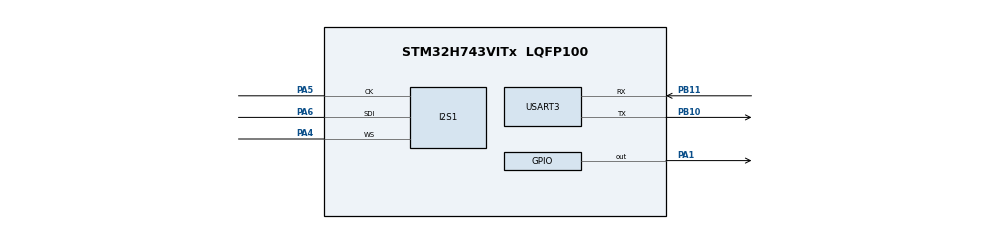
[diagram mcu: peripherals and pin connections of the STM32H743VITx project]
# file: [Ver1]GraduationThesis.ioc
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CORTEX_M7.CPU_DCache=Enabled
CORTEX_M7.CPU_ICache=Enabled
CORTEX_M7.default_mode_Activation=1
Dma.Request0=SPI1_RX
Dma.SPI1_RX.0.Direction=DMA_PERIPH_TO_MEMORY
Dma.SPI1_RX.0.EventEnable=DISABLE
Dma.SPI1_RX.0.FIFOMode=DMA_FIFOMODE_DISABLE
Dma.SPI1_RX.0.Instance=DMA1_Stream0
Dma.SPI1_RX.0.MemDataAlignment=DMA_MDATAALIGN_HALFWORD
Dma.SPI1_RX.0.MemInc=DMA_MINC_ENABLE
Dma.SPI1_RX.0.Mode=DMA_CIRCULAR
Dma.SPI1_RX.0.PeriphDataAlignment=DMA_PDATAALIGN_HALFWORD
Dma.SPI1_RX.0.PeriphInc=DMA_PINC_DISABLE
Dma.SPI1_RX.0.Polarity=HAL_DMAMUX_REQ_GEN_RISING
Dma.SPI1_RX.0.Priority=DMA_PRIORITY_LOW
Dma.SPI1_RX.0.RequestNumber=1
Dma.SPI1_RX.0.SignalID=NONE
Dma.SPI1_RX.0.SyncEnable=DISABLE
Dma.SPI1_RX.0.SyncPolarity=HAL_DMAMUX_SYNC_NO_EVENT
Dma.SPI1_RX.0.SyncRequestNumber=1
Dma.SPI1_RX.0.SyncSignalID=NONE
I2S1.AudioFreq=I2S_AUDIOFREQ_48K
I2S1.ErrorAudioFreq=0.15 %
I2S1.Instance=SPI$Index
I2S1.RealAudioFreq=48.076 KHz
Mcu.Family=STM32H7
Mcu.Name=STM32H743VITx
Mcu.Package=LQFP100
NVIC.DMA1_Stream0_IRQn=true\:0\:0\:false\:false\:true\:false\:true\:true
NVIC.PriorityGroup=NVIC_PRIORITYGROUP_4
NVIC.USART3_IRQn=true\:0\:0\:false\:false\:true\:true\:true\:true
PA1.Signal=GPIO_Output
PA4.Mode=Half_Duplex_Master_Rx
PA4.Signal=I2S1_WS
PA5.Mode=Half_Duplex_Master_Rx
PA5.Signal=I2S1_CK
PA6.Mode=Half_Duplex_Master_Rx
PA6.Signal=I2S1_SDI
PB10.Mode=Asynchronous
PB10.Signal=USART3_TX
PB11.Mode=Asynchronous
PB11.Signal=USART3_RX
PH0-OSC_IN\ (PH0).Mode=HSE-External-Oscillator
PH0-OSC_IN\ (PH0).Signal=RCC_OSC_IN
PH1-OSC_OUT\ (PH1).Mode=HSE-External-Oscillator
PH1-OSC_OUT\ (PH1).Signal=RCC_OSC_OUT
ProjectManager.HeapSize=0x800
ProjectManager.StackSize=0x800
ProjectManager.TargetToolchain=STM32CubeIDE
RCC.ADCFreq_Value=12307692.307692308
RCC.APB1CLKDivider=RCC_HCLK_DIV4
RCC.APB1Freq_Value=120000000
RCC.APB2CLKDivider=RCC_HCLK_DIV2
RCC.APB2Freq_Value=120000000
RCC.APB3Freq_Value=120000000
RCC.APB4Freq_Value=120000000
RCC.CortexFreq_Value=480000000
RCC.D1PPRE=RCC_APB3_DIV2
RCC.D2PPRE1=RCC_APB1_DIV2
RCC.D2PPRE2=RCC_APB2_DIV2
RCC.D3PPRE=RCC_APB4_DIV2
RCC.DIVM1=5
RCC.DIVM2=5
RCC.DIVM3=4
RCC.DIVN1=192
RCC.DIVN2=192
RCC.DIVN3=480
RCC.DIVP2=78
RCC.DIVQ1=20
RCC.DIVQ2=20
RCC.DIVQ3=8
RCC.DIVR2=20
RCC.HCLKFreq_Value=240000000
RCC.HPRE=RCC_HCLK_DIV2
RCC.HSE_VALUE=25000000
RCC.PLLM=25
RCC.PLLMUL=RCC_PLL_MUL9
RCC.PLLN=432
RCC.PLLQ=9
RCC.PLLSourceVirtual=RCC_PLLSOURCE_HSE
RCC.PRESCALERUSB=RCC_USBCLKSOURCE_PLL_DIV1_5
RCC.SPI123CLockSelection=RCC_SPI123CLKSOURCE_PLL2
RCC.SYSCLKFreq_VALUE=480000000
RCC.SYSCLKSource=RCC_SYSCLKSOURCE_PLLCLK
RCC.SYSCLKSourceVirtual=RCC_SYSCLKSOURCE_PLLCLK
RCC.USBFreq_Value=48000000
STMicroelectronics.X-CUBE-AI.10.2.0.ActivationBufferSizeList=127252
STMicroelectronics.X-CUBE-AI.10.2.0.ActivationBuffers=pool0
STMicroelectronics.X-CUBE-AI.10.2.0.ActivationNames=pool0
STMicroelectronics.X-CUBE-AI.10.2.0.ActivationSizes=AI_NETWORK_4_DATA_ACTIVATION_1_SIZE
STMicroelectronics.X-CUBE-AI.10.2.0.ApplicationCcDeviceJjApplication=ApplicationTemplate
STMicroelectronics.X-CUBE-AI.10.2.0.HeapSize=0x800
STMicroelectronics.X-CUBE-AI.10.2.0.InternalRamActivationBufferMaxSize=AI_NETWORK_4_DATA_ACTIVATIONS_SIZE
STMicroelectronics.X-CUBE-AI.10.2.0.LatestDirectoryUsed-b0ac161f105402a51aeaffc1b3403c077ace8f8e6b938b9991d97e17c2f4d924=D\:\\ML
STMicroelectronics.X-CUBE-AI.10.2.0.MaximumNumberOfInputLayer=1
STMicroelectronics.X-CUBE-AI.10.2.0.MaximumNumberOfOutputLayer=1
STMicroelectronics.X-CUBE-AI.10.2.0.MaximumSizeOfInputLayer=1
STMicroelectronics.X-CUBE-AI.10.2.0.MaximumSizeOfOutputLayer=1
STMicroelectronics.X-CUBE-AI.10.2.0.ModelActualCompression-b0ac161f105402a51aeaffc1b3403c077ace8f8e6b938b9991d97e17c2f4d924=0.0
STMicroelectronics.X-CUBE-AI.10.2.0.ModelCompression-b0ac161f105402a51aeaffc1b3403c077ace8f8e6b938b9991d97e17c2f4d924=None
STMicroelectronics.X-CUBE-AI.10.2.0.ModelFlashOccupation-b0ac161f105402a51aeaffc1b3403c077ace8f8e6b938b9991d97e17c2f4d924=55082
STMicroelectronics.X-CUBE-AI.10.2.0.ModelHashList=b0ac161f105402a51aeaffc1b3403c077ace8f8e6b938b9991d97e17c2f4d924
STMicroelectronics.X-CUBE-AI.10.2.0.ModelKind-b0ac161f105402a51aeaffc1b3403c077ace8f8e6b938b9991d97e17c2f4d924=TFLITE
STMicroelectronics.X-CUBE-AI.10.2.0.ModelMacc-b0ac161f105402a51aeaffc1b3403c077ace8f8e6b938b9991d97e17c2f4d924=1861855
STMicroelectronics.X-CUBE-AI.10.2.0.ModelName-b0ac161f105402a51aeaffc1b3403c077ace8f8e6b938b9991d97e17c2f4d924=network_4
STMicroelectronics.X-CUBE-AI.10.2.0.ModelNameList=network_4
STMicroelectronics.X-CUBE-AI.10.2.0.ModelRamOccupation-b0ac161f105402a51aeaffc1b3403c077ace8f8e6b938b9991d97e17c2f4d924=127252
STMicroelectronics.X-CUBE-AI.10.2.0.ModelStructureFile-b0ac161f105402a51aeaffc1b3403c077ace8f8e6b938b9991d97e17c2f4d924=D\:\\ML\\light_cnn_0406_003729_final_float32.tflite
STMicroelectronics.X-CUBE-AI.10.2.0.ModelType-b0ac161f105402a51aeaffc1b3403c077ace8f8e6b938b9991d97e17c2f4d924=STM32Cube.AI MCU runtime
STMicroelectronics.X-CUBE-AI.10.2.0.ReadyForCodeGeneration=true
STMicroelectronics.X-CUBE-AI.10.2.0.StackSize=0x800
STMicroelectronics.X-CUBE-AI.10.2.0.WorkingBufferStartAddrList=0xFFFFFFFF
STMicroelectronics.X-CUBE-AI.10.2.0.XAaCUBEAaAICcArtificialOoIntelligenceJjCore=true
STMicroelectronics.X-CUBE-AI.10.2.0.copyWeightToRam=false
STMicroelectronics.X-CUBE-AI.10.2.0.copyWeightToRam-b0ac161f105402a51aeaffc1b3403c077ace8f8e6b938b9991d97e17c2f4d924=false
STMicroelectronics.X-CUBE-AI.10.2.0.customLayerConfigEnabled=false
STMicroelectronics.X-CUBE-AI.10.2.0.customLayerConfigEnabled-b0ac161f105402a51aeaffc1b3403c077ace8f8e6b938b9991d97e17c2f4d924=false
STMicroelectronics.X-CUBE-AI.10.2.0.noOnnxIoTranspose=false
STMicroelectronics.X-CUBE-AI.10.2.0.noOnnxIoTranspose-b0ac161f105402a51aeaffc1b3403c077ace8f8e6b938b9991d97e17c2f4d924=false
STMicroelectronics.X-CUBE-AI.10.2.0.useInputAllocation=true
STMicroelectronics.X-CUBE-AI.10.2.0.useInputAllocation-b0ac161f105402a51aeaffc1b3403c077ace8f8e6b938b9991d97e17c2f4d924=true
STMicroelectronics.X-CUBE-AI.10.2.0.useOutputAllocation=true
STMicroelectronics.X-CUBE-AI.10.2.0.useOutputAllocation-b0ac161f105402a51aeaffc1b3403c077ace8f8e6b938b9991d97e17c2f4d924=true
USART3.VirtualMode-Asynchronous=VM_ASYNC
VP_MEMORYMAP_VS_MEMORYMAP.Mode=CurAppReg
VP_STMicroelectronics.X-CUBE-AI_VS_ArtificialOoIntelligenceJjXAaCUBEAaAI_10.2.0.Mode=ArtificialOoIntelligenceJjXAaCUBEAaAI
VP_STMicroelectronics.X-CUBE-AI_VS_DeviceJjApplication_10.2.0.Mode=DeviceJjApplication
board=custom

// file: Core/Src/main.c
/* USER CODE BEGIN Header */
/**
 ******************************************************************************
 * @file           : main.c
 * @brief          : Main program body
 ******************************************************************************
 */
/* USER CODE END Header */
#include "main.h"
#include "app_x-cube-ai.h"
#include <string.h>
/* USER CODE BEGIN Includes */
#include "audio_capture.h" // định nghĩa FRAME_LEN, HOP_SAMPLES, RING_BUFFER_SIZE
#include "mfcc_extract.h"
#include "debug_uart.h"
/* USER CODE END Includes */
#define INFER_STEP_FRAMES 67U // ~1 giây vì hop = 15 ms

I2S_HandleTypeDef hi2s1;
DMA_HandleTypeDef hdma_spi1_rx;

UART_HandleTypeDef huart3;
static int16_t mfcc_audio_frame[FRAME_LEN];
static uint8_t mfcc_frame_initialized = 0;
static uint32_t new_frames_since_infer = 0;
static uint8_t first_inference_done = 0;
static uint8_t mfcc_window_ready = 0;

void SystemClock_Config(void);
static void MPU_Config(void);
static void MX_GPIO_Init(void);
static void MX_DMA_Init(void);
static void MX_I2S1_Init(void);
static void MX_USART3_UART_Init(void);
void MFCC_LogWindowTiming(void);

/* USER CODE BEGIN 0 */
extern int16_t ring_buffer[];
extern volatile uint32_t rb_write;
extern volatile uint32_t rb_read;
extern float32_t mfcc_final_features[MFCC_FEATURES][MFCC_TIME_FRAMES];
extern uint32_t mfcc_collected;
/* USER CODE END 0 */

int main(void)
{

  /* MPU Configuration--------------------------------------------------------*/
  MPU_Config();

  /* Enable the CPU Cache */

  /* Enable I-Cache---------------------------------------------------------*/
  SCB_EnableICache();

  /* Enable D-Cache---------------------------------------------------------*/
  SCB_EnableDCache();

  /* MCU Configuration--------------------------------------------------------*/

  /* Reset of all peripherals, Initializes the Flash interface and the Systick. */
  HAL_Init();

  /* Configure the system clock */
  SystemClock_Config();

  /* Initialize all configured peripherals */
  MX_GPIO_Init();
  MX_DMA_Init();
  MX_I2S1_Init();
  MX_USART3_UART_Init();
  MX_X_CUBE_AI_Init();

  DebugUART_InitTime();
  DebugUART_Log("Hello STM32H743\r\n");
  /* USER CODE BEGIN 2 */
  Preprocessing_Init();
  StartAudioCapture();
  /* USER CODE END 2 */

  /* Infinite loop */
  /* USER CODE BEGIN WHILE */
  while (1)
  {
    Audio_DebugLog_Process();

    if (!mfcc_frame_initialized)
    {
      if (RingBuffer_Available() >= FRAME_LEN)
      {
        RingBuffer_Read(mfcc_audio_frame, FRAME_LEN);
        mfcc_frame_initialized = 1;
      }
    }

    while (mfcc_frame_initialized &&
           RingBuffer_Available() >= HOP_SAMPLES)
    {
      int16_t hop_buf[HOP_SAMPLES];
      float mfcc_frame[MFCC_FEATURES];

      RingBuffer_Read(hop_buf, HOP_SAMPLES);

      memmove(&mfcc_audio_frame[0],
              &mfcc_audio_frame[HOP_SAMPLES],
              (FRAME_LEN - HOP_SAMPLES) * sizeof(int16_t));

      memcpy(&mfcc_audio_frame[FRAME_LEN - HOP_SAMPLES],
             hop_buf,
             HOP_SAMPLES * sizeof(int16_t));

      compute_mfcc_one_frame_timed(mfcc_audio_frame, mfcc_frame);
      mfcc_append_frame(mfcc_frame);

      if (!first_inference_done && mfcc_collected >= MFCC_TIME_FRAMES)
      {
        MFCC_DebugLog_Window();

        MX_X_CUBE_AI_Process();

        first_inference_done = 1;
        new_frames_since_infer = 0;

        MFCC_DebugReset_Window();
        break;
      }
      else if (first_inference_done)
      {
        new_frames_since_infer++;

        if (new_frames_since_infer >= INFER_STEP_FRAMES)
        {
          MFCC_DebugLog_Window();

          MX_X_CUBE_AI_Process();

          new_frames_since_infer = 0;

          MFCC_DebugReset_Window();
          break;
        }
      }
    }
  }
  /* USER CODE END 3 */
}
void MFCC_LogWindowTiming(void)
{
  uint32_t window_elapsed = HAL_GetTick() - mfcc_window_start_ms;
  uint32_t avg_ms = (mfcc_frame_count > 0)
                        ? (mfcc_time_total_ms / mfcc_frame_count)
                        : 0;

  DebugUART_Log(
      "[MFCC] window=%lu ms | frames=%lu | compute: total=%lu ms avg=%lu ms max=%lu ms\r\n",
      window_elapsed,
      mfcc_frame_count,
      mfcc_time_total_ms,
      avg_ms,
      mfcc_time_max_ms);

  /* Reset cho window tiếp theo */
  mfcc_frame_count = 0;
  mfcc_time_total_ms = 0;
  mfcc_time_max_ms = 0;
  mfcc_window_start_ms = HAL_GetTick();
}
void SystemClock_Config(void)
{
  RCC_OscInitTypeDef RCC_OscInitStruct = {0};
  RCC_ClkInitTypeDef RCC_ClkInitStruct = {0};

  /** Supply configuration update enable
   */
  HAL_PWREx_ConfigSupply(PWR_LDO_SUPPLY);

  /** Configure the main internal regulator output voltage
   */
  __HAL_PWR_VOLTAGESCALING_CONFIG(PWR_REGULATOR_VOLTAGE_SCALE0);

  while (!__HAL_PWR_GET_FLAG(PWR_FLAG_VOSRDY))
  {
  }

  /** Initializes the RCC Oscillators according to the specified parameters
   * in the RCC_OscInitTypeDef structure.
   */
  RCC_OscInitStruct.OscillatorType = RCC_OSCILLATORTYPE_HSE;
  RCC_OscInitStruct.HSEState = RCC_HSE_ON;
  RCC_OscInitStruct.PLL.PLLState = RCC_PLL_ON;
  RCC_OscInitStruct.PLL.PLLSource = RCC_PLLSOURCE_HSE;
  RCC_OscInitStruct.PLL.PLLM = 5;
  RCC_OscInitStruct.PLL.PLLN = 192;
  RCC_OscInitStruct.PLL.PLLP = 2;
  RCC_OscInitStruct.PLL.PLLQ = 20;
  RCC_OscInitStruct.PLL.PLLR = 2;
  RCC_OscInitStruct.PLL.PLLRGE = RCC_PLL1VCIRANGE_2;
  RCC_OscInitStruct.PLL.PLLVCOSEL = RCC_PLL1VCOWIDE;
  RCC_OscInitStruct.PLL.PLLFRACN = 0;
  if (HAL_RCC_OscConfig(&RCC_OscInitStruct) != HAL_OK)
  {
    Error_Handler();
  }

  /** Initializes the CPU, AHB and APB buses clocks
   */
  RCC_ClkInitStruct.ClockType = RCC_CLOCKTYPE_HCLK | RCC_CLOCKTYPE_SYSCLK | RCC_CLOCKTYPE_PCLK1 | RCC_CLOCKTYPE_PCLK2 | RCC_CLOCKTYPE_D3PCLK1 | RCC_CLOCKTYPE_D1PCLK1;
  RCC_ClkInitStruct.SYSCLKSource = RCC_SYSCLKSOURCE_PLLCLK;
  RCC_ClkInitStruct.SYSCLKDivider = RCC_SYSCLK_DIV1;
  RCC_ClkInitStruct.AHBCLKDivider = RCC_HCLK_DIV2;
  RCC_ClkInitStruct.APB3CLKDivider = RCC_APB3_DIV2;
  RCC_ClkInitStruct.APB1CLKDivider = RCC_APB1_DIV2;
  RCC_ClkInitStruct.APB2CLKDivider = RCC_APB2_DIV2;
  RCC_ClkInitStruct.APB4CLKDivider = RCC_APB4_DIV2;

  if (HAL_RCC_ClockConfig(&RCC_ClkInitStruct, FLASH_LATENCY_4) != HAL_OK)
  {
    Error_Handler();
  }
}

static void MX_I2S1_Init(void)
{

  hi2s1.Instance = SPI1;
  hi2s1.Init.Mode = I2S_MODE_MASTER_RX;
  hi2s1.Init.Standard = I2S_STANDARD_PHILIPS;
  hi2s1.Init.DataFormat = I2S_DATAFORMAT_16B;
  hi2s1.Init.MCLKOutput = I2S_MCLKOUTPUT_DISABLE;
  hi2s1.Init.AudioFreq = I2S_AUDIOFREQ_48K;
  hi2s1.Init.CPOL = I2S_CPOL_LOW;
  hi2s1.Init.FirstBit = I2S_FIRSTBIT_MSB;
  hi2s1.Init.WSInversion = I2S_WS_INVERSION_DISABLE;
  hi2s1.Init.Data24BitAlignment = I2S_DATA_24BIT_ALIGNMENT_RIGHT;
  hi2s1.Init.MasterKeepIOState = I2S_MASTER_KEEP_IO_STATE_DISABLE;
  if (HAL_I2S_Init(&hi2s1) != HAL_OK)
  {
    Error_Handler();
  }
}

static void MX_USART3_UART_Init(void)
{

  huart3.Instance = USART3;
  huart3.Init.BaudRate = 115200;
  huart3.Init.WordLength = UART_WORDLENGTH_8B;
  huart3.Init.StopBits = UART_STOPBITS_1;
  huart3.Init.Parity = UART_PARITY_NONE;
  huart3.Init.Mode = UART_MODE_TX_RX;
  huart3.Init.HwFlowCtl = UART_HWCONTROL_NONE;
  huart3.Init.OverSampling = UART_OVERSAMPLING_16;
  huart3.Init.OneBitSampling = UART_ONE_BIT_SAMPLE_DISABLE;
  huart3.Init.ClockPrescaler = UART_PRESCALER_DIV1;
  huart3.AdvancedInit.AdvFeatureInit = UART_ADVFEATURE_NO_INIT;
  if (HAL_UART_Init(&huart3) != HAL_OK)
  {
    Error_Handler();
  }
  if (HAL_UARTEx_SetTxFifoThreshold(&huart3, UART_TXFIFO_THRESHOLD_1_8) != HAL_OK)
  {
    Error_Handler();
  }
  if (HAL_UARTEx_SetRxFifoThreshold(&huart3, UART_RXFIFO_THRESHOLD_1_8) != HAL_OK)
  {
    Error_Handler();
  }
  if (HAL_UARTEx_DisableFifoMode(&huart3) != HAL_OK)
  {
    Error_Handler();
  }
}

static void MX_DMA_Init(void)
{

  /* DMA controller clock enable */
  __HAL_RCC_DMA1_CLK_ENABLE();

  /* DMA interrupt init */
  /* DMA1_Stream0_IRQn interrupt configuration */
  HAL_NVIC_SetPriority(DMA1_Stream0_IRQn, 0, 0);
  HAL_NVIC_EnableIRQ(DMA1_Stream0_IRQn);
}

static void MX_GPIO_Init(void)
{
  GPIO_InitTypeDef GPIO_InitStruct = {0};

  /* GPIO Ports Clock Enable */
  __HAL_RCC_GPIOH_CLK_ENABLE();
  __HAL_RCC_GPIOA_CLK_ENABLE();
  __HAL_RCC_GPIOB_CLK_ENABLE();

  /*Configure GPIO pin Output Level */
  HAL_GPIO_WritePin(GPIOA, GPIO_PIN_1, GPIO_PIN_RESET);

  /*Configure GPIO pin : PA1 */
  GPIO_InitStruct.Pin = GPIO_PIN_1;
  GPIO_InitStruct.Mode = GPIO_MODE_OUTPUT_PP;
  GPIO_InitStruct.Pull = GPIO_NOPULL;
  GPIO_InitStruct.Speed = GPIO_SPEED_FREQ_LOW;
  HAL_GPIO_Init(GPIOA, &GPIO_InitStruct);

  /*AnalogSwitch Config */
  HAL_SYSCFG_AnalogSwitchConfig(SYSCFG_SWITCH_PA1, SYSCFG_SWITCH_PA1_CLOSE);

}

/* MPU Configuration */

void MPU_Config(void)
{
  MPU_Region_InitTypeDef MPU_InitStruct = {0};

  /* Disables the MPU */
  HAL_MPU_Disable();

  /** Initializes and configures the Region and the memory to be protected
   */
  MPU_InitStruct.Enable = MPU_REGION_ENABLE;
  MPU_InitStruct.Number = MPU_REGION_NUMBER0;
  MPU_InitStruct.BaseAddress = 0x0;
  MPU_InitStruct.Size = MPU_REGION_SIZE_4GB;
  MPU_InitStruct.SubRegionDisable = 0x87;
  MPU_InitStruct.TypeExtField = MPU_TEX_LEVEL0;
  MPU_InitStruct.AccessPermission = MPU_REGION_NO_ACCESS;
  MPU_InitStruct.DisableExec = MPU_INSTRUCTION_ACCESS_DISABLE;
  MPU_InitStruct.IsShareable = MPU_ACCESS_SHAREABLE;
  MPU_InitStruct.IsCacheable = MPU_ACCESS_NOT_CACHEABLE;
  MPU_InitStruct.IsBufferable = MPU_ACCESS_NOT_BUFFERABLE;

  HAL_MPU_ConfigRegion(&MPU_InitStruct);
  /* Enables the MPU */
  HAL_MPU_Enable(MPU_PRIVILEGED_DEFAULT);
}

void Error_Handler(void)
{
  __disable_irq();
  while (1)
  {
  }
}
